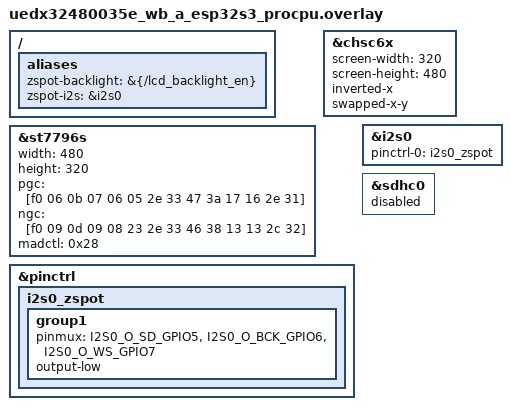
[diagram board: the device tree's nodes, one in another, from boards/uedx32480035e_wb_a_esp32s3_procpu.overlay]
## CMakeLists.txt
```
# Copyright (c) 2026 Muhammad Waleed Badar
# SPDX-License-Identifier: GPL-3.0-only

cmake_minimum_required(VERSION 3.20.0)

# When built from another west workspace, point Zephyr at this module.
if(NOT DEFINED ZEPHYR_EXTRA_MODULES)
  set(ZEPHYR_EXTRA_MODULES ${CMAKE_CURRENT_SOURCE_DIR}/..)
endif()

find_package(Zephyr REQUIRED HINTS $ENV{ZEPHYR_BASE})
project(zspot_player)

# --- Sources --------------------------------------------------------------

target_sources(app PRIVATE
  src/main.c
  src/certs.c
  src/webapi.c
  src/json_scan.c
)

target_sources_ifdef(CONFIG_WIFI_CREDENTIALS_CONNECT_STORED app PRIVATE src/wifi.c)
target_sources_ifdef(CONFIG_ZSPOT_CREDENTIALS_STORED        app PRIVATE src/credentials.c)
target_sources_ifdef(CONFIG_SETTINGS                        app PRIVATE src/track.c)
target_sources_ifdef(CONFIG_ZSPOT_PCM_TAP                   app PRIVATE src/pcm_tap.c)
target_sources_ifdef(CONFIG_ZSPOT_BATTERY                   app PRIVATE src/battery.c)

target_sources_ifdef(CONFIG_ZSPOT_UI app PRIVATE
  src/ui.c
  src/cover.c
  src/library.c
  src/lyrics.c
)

# --- TLS ------------------------------------------------------------------

# Mbed TLS is built with zspot_mbedtls_config.h (CONFIG_MBEDTLS_USER_CONFIG_FILE)
zephyr_include_directories(mbedtls)

# The root certificates that the servers are verified against
set(root_certs
  digicert_global_root_g2
  digicert_global_root_g3
  globalsign_root_r3
  gts_root_r4
  starfield_root_g2
)
foreach(cert ${root_certs})
  generate_inc_file_for_target(app
    certs/${cert}.der
    ${ZEPHYR_BINARY_DIR}/include/generated/certs/${cert}.der.inc
  )
endforeach()

# --- native_sim: west build -t run_tap ------------------------------------

if(CONFIG_ETH_NATIVE_TAP)
  if(DEFINED ENV{ZEPHYR_NET_TOOLS})
    set(net_tools $ENV{ZEPHYR_NET_TOOLS})
  else()
    set(net_tools ${ZEPHYR_BASE}/../tools/net-tools)
  endif()

  set(run_script ${CMAKE_CURRENT_SOURCE_DIR}/../scripts/native_sim_run.py)
  set(player     ${APPLICATION_BINARY_DIR}/zephyr/${KERNEL_EXE_NAME})

  add_custom_target(run_tap
    COMMAND ${PYTHON_EXECUTABLE} ${run_script} --net-tools ${net_tools} ${player}
    DEPENDS
      ${logical_target_for_zephyr_elf}
      $<$<TARGET_EXISTS:native_runner_executable>:native_runner_executable>
    WORKING_DIRECTORY ${APPLICATION_BINARY_DIR}
    USES_TERMINAL
  )
endif()
```

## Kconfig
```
# Copyright (c) 2026 Muhammad Waleed Badar
# SPDX-License-Identifier: GPL-3.0-only

mainmenu "zspot player"

menu "zspot player"

config ZSPOT_PCM_TAP
	bool "PCM tap: copy of the audio over TCP"
	select RING_BUFFER_LARGE
	help
	  Starts a TCP server that sends a copy of the PCM handed to the sink
	  (16-bit little-endian stereo at 44.1 kHz, before the sink applies the
	  volume) to a client, to hear on another machine what the output is
	  fed with:

	    nc <device> <port> | aplay -f S16_LE -r 44100 -c 2 \
	        -B 1000000 -R 1000000

	  A diagnostic aid: when the copy sounds right but the DAC does not,
	  the fault is in the I2S configuration, the wiring or the DAC.

config ZSPOT_PCM_TAP_PORT
	int "TCP port of the PCM tap"
	default 5000
	depends on ZSPOT_PCM_TAP

choice ZSPOT_AUDIO_QUALITY
	prompt "Stream quality"
	default ZSPOT_AUDIO_QUALITY_160
	help
	  Bit rate of the Ogg Vorbis stream that is asked for. A track that
	  does not come in it is played at 96 kbit/s. More takes more of the
	  network and of the processor.

config ZSPOT_AUDIO_QUALITY_96
	bool "96 kbit/s"

config ZSPOT_AUDIO_QUALITY_160
	bool "160 kbit/s"

config ZSPOT_AUDIO_QUALITY_320
	bool "320 kbit/s"

endchoice

config ZSPOT_AUDIO_FORMAT
	int
	default 0 if ZSPOT_AUDIO_QUALITY_96
	default 2 if ZSPOT_AUDIO_QUALITY_320
	default 1

config ZSPOT_USERNAME
	string "Spotify username (development only)"
	default ""
	help
	  Together with ZSPOT_PASSWORD, logs in with a username and
	  password instead of the zeroconf hand-over. Spotify no longer accepts
	  password logins from third-party clients for most accounts, but the
	  attempt still exercises access point resolution, the handshake and
	  the authentication exchange, which is useful on native_sim.

config ZSPOT_PASSWORD
	string "Spotify password (development only)"
	default ""

config ZSPOT_CREDENTIALS_JSON
	string "Stored credentials (JSON)"
	default ""
	help
	  Output of zspot_credentials_save_json() from a previous session. When
	  set, the sample skips the zeroconf hand-over.

config ZSPOT_CREDENTIALS_STORED
	bool "Keep the Spotify and the Web API credentials on the device"
	default y
	depends on SETTINGS
	select SECURE_STORAGE
	help
	  Stores the reusable credentials of a session in the settings and
	  signs in with them at the next start, so that the device does not
	  have to be picked in the Spotify app again. Credentials that Spotify
	  rejects are removed, and the device waits for the hand-over again.

	  The device then stays signed in to the account that picked it last,
	  until another one picks it in its Spotify app.

	  The credentials of the Web API are kept the same way, once a build
	  has carried them to the device (ZSPOT_WEB_CREDENTIALS_BUILT_IN).

	  Both go through the secure storage subsystem, which encrypts them
	  (AES-GCM) with a key derived from the ID of the device before they
	  reach the settings. That keeps them out of a plain copy of the
	  flash; it is no protection from somebody who also reads the device
	  ID, which takes the flash encryption of the SoC. Zephyr's Wi-Fi
	  credentials library keeps the Wi-Fi passwords in the secure storage
	  as well.

	  Credentials given to the build (ZSPOT_CREDENTIALS_JSON, or
	  ZSPOT_USERNAME and ZSPOT_PASSWORD) take precedence over stored ones.

# The credentials of a session are a JSON text of a few hundred bytes
configdefault SECURE_STORAGE_ITS_MAX_DATA_SIZE
	default 1024 if ZSPOT_CREDENTIALS_STORED

config ZSPOT_WEB_CREDENTIALS_BUILT_IN
	bool "Build the Web API credentials into the firmware"
	help
	  The last song after a restart, and "Your Library" and the search on
	  the Now Playing screen, use the Spotify Web API, which needs an
	  application registered at developer.spotify.com and a one-time
	  authorisation by the user with scripts/spotify_authorize.py. That
	  gives a client ID, a client secret and a refresh token.

	  With this option the build takes the three from its environment
	  (ZSPOT_WEB_CLIENT_ID, ZSPOT_WEB_CLIENT_SECRET and
	  ZSPOT_WEB_REFRESH_TOKEN) and makes them part of the firmware, where
	  they are plain text: whoever has the firmware file can read them.

	  A player that keeps credentials (ZSPOT_CREDENTIALS_STORED) stores
	  them encrypted at its first start and uses the stored ones from then
	  on. Build it with this option once, to carry them to the device, and
	  without it afterwards, so that the firmware no longer holds them.
	  Building with it again replaces the stored ones.

	  A player that has nowhere to store them has to be built with it
	  every time. Without credentials the library view only says that it
	  is not set up, and the last song is not offered after a restart.

if ZSPOT_WEB_CREDENTIALS_BUILT_IN

# The defaults come from the environment of the build, so that the values stay
# out of the repository and of the command line.

config ZSPOT_WEB_CLIENT_ID
	string "Client ID of the Spotify developer application"
	default "$(ZSPOT_WEB_CLIENT_ID)"

config ZSPOT_WEB_CLIENT_SECRET
	string "Client secret of the Spotify developer application"
	default "$(ZSPOT_WEB_CLIENT_SECRET)"

config ZSPOT_WEB_REFRESH_TOKEN
	string "Refresh token of the authorised user"
	default "$(ZSPOT_WEB_REFRESH_TOKEN)"

endif # ZSPOT_WEB_CREDENTIALS_BUILT_IN

config ZSPOT_UI
	bool "Now Playing screen (LVGL)"
	depends on LVGL && LV_Z_RUN_LVGL_ON_WORKQUEUE && LV_USE_TJPGD
	help
	  Shows the cover art, title, artist and progress of the current track
	  on the chosen display (the layout follows its resolution) and offers touch
	  controls for play/pause, skipping, seeking and the volume. See
	  prj.conf for the LVGL configuration it needs, and boards/<board>.conf
	  for what depends on the display of a board.

if ZSPOT_UI

config ZSPOT_BATTERY
	bool "Battery indicator"
	default y
	depends on $(dt_alias_enabled,fuel-gauge0)
	select FUEL_GAUGE
	help
	  Shows the charge level reported by the fuel gauge behind the
	  devicetree alias fuel-gauge0 next to the network indicator. Only
	  available when the board has that alias and its node is enabled.

config ZSPOT_BATTERY_POLL_SECONDS
	int "Seconds between two readings of the fuel gauge"
	default 30
	range 1 3600

config ZSPOT_SCREEN_TIMEOUT_SECONDS
	int "Seconds without a touch after which the screen turns off"
	default 60
	range 0 3600
	help
	  Turns the display off, and its backlight when the board has the
	  devicetree alias zspot-backlight (a regulator), once the screen has
	  not been touched for this long. The next touch turns it back on and
	  does nothing else. Playback is not affected. 0 keeps the screen on.

endif # ZSPOT_UI

endmenu # zspot player

source "Kconfig.zephyr"
```

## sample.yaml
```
# Copyright (c) 2026 Muhammad Waleed Badar
# SPDX-License-Identifier: GPL-3.0-only

sample:
  name: zspot player
  description: Spotify Connect player with a touchscreen UI (Now Playing, library, lyrics, Wi-Fi setup)
common:
  build_only: true
  tags: zspot
  platform_allow:
    - native_sim/native/64
  integration_platforms:
    - native_sim/native/64
tests:
  # As it is flashed and run
  app.zspot.player:
    platform_allow:
      - native_sim/native/64
      - uedx32480035e_wb_a/esp32s3/procpu
    integration_platforms:
      - native_sim/native/64
      - uedx32480035e_wb_a/esp32s3/procpu
  # What the board has and native_sim lacks: the settings, and with them the
  # stored credentials and the last song
  app.zspot.player.settings:
    extra_configs:
      - CONFIG_FLASH=y
      - CONFIG_FLASH_MAP=y
      - CONFIG_NVS=y
      - CONFIG_SETTINGS=y
  app.zspot.player.no_ui:
    extra_configs:
      - CONFIG_ZSPOT_UI=n
  # The stored credentials, the last song and the Web API do not need the screen
  app.zspot.player.no_ui.settings:
    extra_configs:
      - CONFIG_ZSPOT_UI=n
      - CONFIG_FLASH=y
      - CONFIG_FLASH_MAP=y
      - CONFIG_NVS=y
      - CONFIG_SETTINGS=y
  app.zspot.player.debug:
    extra_args: EXTRA_CONF_FILE=debug.conf
  # Options that leave code out or swap it: the PCM tap, the sink without a
  # buffer ahead of the output, servers that are not verified
  app.zspot.player.options:
    extra_configs:
      - CONFIG_ZSPOT_PCM_TAP=y
      - CONFIG_ZSPOT_I2S_BUFFER_MS=0
      - CONFIG_ZSPOT_TLS_SEC_TAG=-1
```

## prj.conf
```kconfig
# Copyright (c) 2026 Muhammad Waleed Badar
# SPDX-License-Identifier: GPL-3.0-only

# --- zspot ---------------------------------------------------------------
CONFIG_ZSPOT=y
CONFIG_ZSPOT_I2S_SINK=y
CONFIG_ZSPOT_UI=y

# --- C++ runtime for the protocol core -----------------------------------
CONFIG_CPP=y
CONFIG_STD_CPP20=y

# --- Memory ---------------------------------------------------------------
CONFIG_MAIN_STACK_SIZE=8192
# Wi-Fi connect requests run on the system workqueue; the Wi-Fi driver starts
# up in the caller's context, and the stored networks are read there through
# the secure storage, with buffers of an entry's size on the stack. That took
# 4.2 KB.
CONFIG_SYSTEM_WORKQUEUE_STACK_SIZE=6144
CONFIG_DYNAMIC_THREAD_POOL_SIZE=0
CONFIG_DYNAMIC_THREAD_PREFER_ALLOC=y

# --- Networking -----------------------------------------------------------
CONFIG_NETWORKING=y
CONFIG_NET_IPV4=y
CONFIG_NET_IPV6=n
CONFIG_NET_TCP=y
CONFIG_NET_UDP=y
CONFIG_NET_SOCKETS=y
CONFIG_NET_DHCPV4=y
CONFIG_NET_MGMT=y
CONFIG_NET_MGMT_EVENT=y
CONFIG_NET_MGMT_EVENT_INFO=y
CONFIG_NET_CONNECTION_MANAGER=n
CONFIG_NET_HOSTNAME_ENABLE=y
CONFIG_NET_HOSTNAME="zspot"
# The TCP receive window is a third of the RX buffer space (128 bytes each).
# With 64 buffers it was 2.7 KB, less than two segments, which throttled the
# audio download; 768 buffers make it 32 KB.
CONFIG_NET_PKT_RX_COUNT=64
CONFIG_NET_BUF_RX_COUNT=768
CONFIG_NET_PKT_TX_COUNT=64
CONFIG_NET_BUF_TX_COUNT=768
# The audio CDN, the track look-up, the cover, the lyrics and the Web API at a
# track change, the access point, the two endpoints that listen, mDNS, DNS and
# DHCP, and connections that were closed a moment ago and still linger: with
# 12, a few requests in a row to an endpoint were refused
CONFIG_NET_MAX_CONN=16
CONFIG_NET_MAX_CONTEXTS=16

CONFIG_NET_RX_STACK_SIZE=4096
CONFIG_NET_TCP_WORKQ_STACK_SIZE=4096
# The thread that takes DNS answers and answers mDNS queries. On the ESP32-S3
# an answer to a browse for the Spotify Connect service takes 1.6 KB of stack,
# more than the 1536 bytes that Zephyr gives it with the mDNS responder
CONFIG_NET_SOCKETS_SERVICE_STACK_SIZE=2560

CONFIG_ZVFS_OPEN_MAX=20
CONFIG_ZVFS_POLL_MAX=16

# DNS: resolver gets the servers from DHCP, static fallback below
CONFIG_DNS_RESOLVER=y
CONFIG_DNS_SERVER_IP_ADDRESSES=y
CONFIG_DNS_SERVER1="8.8.8.8"
CONFIG_DNS_RESOLVER_MAX_SERVERS=3
# At a track change the audio CDN, the cover, the lyrics and the Web API are
# looked up at the same time; with the default of one query at a time the
# others fail at once ("DNS lookup ... failed (-3)")
CONFIG_DNS_NUM_CONCUR_QUERIES=4

# mDNS / DNS-SD for discovery by the Spotify app
CONFIG_MDNS_RESPONDER=y
CONFIG_DNS_SD=y
CONFIG_MDNS_RESPONDER_DNS_SD=y

# --- TLS (Spotify endpoints: TLS 1.2, ECDHE-RSA, AES-GCM) -----------------
CONFIG_MBEDTLS=y
CONFIG_MBEDTLS_ENABLE_HEAP=y
# Sessions: access point resolution/metadata, audio CDN and the cover art
CONFIG_MBEDTLS_HEAP_SIZE=163840
CONFIG_MBEDTLS_SSL_IN_CONTENT_LEN=16384
CONFIG_MBEDTLS_SSL_OUT_CONTENT_LEN=4096
CONFIG_MBEDTLS_SSL_PROTO_TLS1_2=y
CONFIG_MBEDTLS_SSL_SERVER_NAME_INDICATION=y
CONFIG_MBEDTLS_KEY_EXCHANGE_ECDHE_RSA_ENABLED=y
CONFIG_MBEDTLS_CIPHERSUITE_TLS_ECDHE_RSA_WITH_AES_128_GCM_SHA256=y
CONFIG_MBEDTLS_CIPHERSUITE_TLS_ECDHE_RSA_WITH_AES_256_GCM_SHA384=y
# The lyrics service (lrclib.net) only offers ECDSA certificates
CONFIG_MBEDTLS_KEY_EXCHANGE_ECDHE_ECDSA_ENABLED=y
CONFIG_MBEDTLS_CIPHERSUITE_TLS_ECDHE_ECDSA_WITH_AES_128_GCM_SHA256=y
CONFIG_MBEDTLS_X509_CRT_PARSE_C=y
# The AES tables come with the image instead of being computed into 8 KB of
# RAM at the first use
CONFIG_MBEDTLS_AES_ROM_TABLES=y
CONFIG_PSA_CRYPTO=y
CONFIG_PSA_WANT_ALG_SHA_256=y
CONFIG_PSA_WANT_ALG_SHA_384=y
CONFIG_PSA_WANT_ALG_GCM=y
CONFIG_PSA_WANT_ALG_ECDH=y
CONFIG_PSA_WANT_ECC_SECP_R1_256=y
CONFIG_PSA_WANT_ECC_SECP_R1_384=y
CONFIG_PSA_WANT_KEY_TYPE_ECC_KEY_PAIR_GENERATE=y
CONFIG_PSA_WANT_ALG_RSA_PKCS1V15_SIGN=y
CONFIG_PSA_WANT_ALG_ECDSA=y
CONFIG_PSA_WANT_KEY_TYPE_ECC_PUBLIC_KEY=y
CONFIG_PSA_WANT_KEY_TYPE_RSA_PUBLIC_KEY=y
CONFIG_NET_SOCKETS_SOCKOPT_TLS=y
CONFIG_NET_SOCKETS_TLS_MAX_CONTEXTS=6
# The servers are verified against the root certificates in certs/, which the
# application registers under these tags. A tag of -1 turns that off.
CONFIG_TLS_CREDENTIALS=y
CONFIG_TLS_MAX_CREDENTIALS_NUMBER=8
CONFIG_NET_SOCKETS_TLS_MAX_CREDENTIALS=8
CONFIG_ZSPOT_TLS_SEC_TAG=100
CONFIG_ZSPOT_TLS_SEC_TAG_COUNT=5
# Sessions that are resumed instead of negotiated anew: one per server that is
# connected to again and again (track look-up, audio CDN, cover, Web API and
# its token, lyrics). The tickets for that come with zspot_mbedtls_config.h.
CONFIG_NET_SOCKETS_TLS_MAX_CLIENT_SESSION_COUNT=6
CONFIG_MBEDTLS_USER_CONFIG_FILE="zspot_mbedtls_config.h"
CONFIG_ENTROPY_GENERATOR=y

# --- Display: "Now Playing" screen (LVGL) ----------------------------------
# What depends on the display of a board is in boards/<board>.conf: its colour
# depth and formats, larger fonts, where the memory pool lives.
CONFIG_DISPLAY=y
CONFIG_INPUT=y
# Touch events queue up while the LVGL thread is busy (e.g. in a zspot call);
# with the default sizes drags lose events ("Could not put input data into
# queue")
CONFIG_INPUT_QUEUE_MAX_MSGS=64
CONFIG_LV_Z_POINTER_INPUT_MSGQ_COUNT=64
CONFIG_LVGL=y
CONFIG_LV_Z_POINTER_INPUT=y
# LVGL runs on its own workqueue; the touch handlers call into zspot from it
# (protobuf encoding, socket I/O), hence the stack
CONFIG_LV_Z_RUN_LVGL_ON_WORKQUEUE=y
CONFIG_LV_Z_LVGL_MUTEX=y
CONFIG_LV_Z_LVGL_WORKQUEUE_STACK_SIZE=16384
# Below the zspot threads (CONFIG_ZSPOT_THREAD_PRIORITY and higher): drawing
# must not take the processor from the audio decoder
CONFIG_LV_Z_LVGL_WORKQUEUE_PRIORITY=8
CONFIG_LV_Z_FLUSH_THREAD=y
CONFIG_LV_Z_FLUSH_THREAD_PRIORITY=8
# Holds the widgets, the cover art (the downloaded JPEG, up to 96 KB, and the
# decoded RGB565 image, 180 KB at 300x300, briefly two of the latter), the
# Web API responses of the library view (160 KB) and the lyrics (80 KB while
# they load)
CONFIG_LV_Z_MEM_POOL_SIZE=1048576
CONFIG_LV_USE_LABEL=y
CONFIG_LV_USE_IMAGE=y
CONFIG_LV_USE_BAR=y
CONFIG_LV_USE_SLIDER=y
# Password entry of the Wi-Fi settings
CONFIG_LV_USE_TEXTAREA=y
CONFIG_LV_USE_BUTTONMATRIX=y
CONFIG_LV_USE_KEYBOARD=y
CONFIG_LV_THEME_DEFAULT_DARK=y
# The covers are JPEG
CONFIG_LV_USE_TJPGD=y
# The fonts of a 320x480 display. The UI scales with the resolution: a board
# with a larger display adds 18, 30 and 40 (one and a half times the size) or
# 24, 40 and 48 (twice the size) in boards/<board>.conf, and the UI takes them.
CONFIG_LV_FONT_MONTSERRAT_12=y
CONFIG_LV_FONT_MONTSERRAT_14=y
CONFIG_LV_FONT_MONTSERRAT_20=y
CONFIG_LV_FONT_MONTSERRAT_28=y

# --- Wi-Fi (wifi_credentials library, settings/NVS backend) ----------------
# The Wi-Fi driver is selected per board; boards without Wi-Fi override this
# block (see boards/native_sim_native_64.conf).
CONFIG_WIFI=y
CONFIG_WIFI_CREDENTIALS=y
CONFIG_WIFI_CREDENTIALS_CONNECT_STORED=y
CONFIG_FLASH=y
CONFIG_FLASH_MAP=y
CONFIG_NVS=y
CONFIG_SETTINGS=y
CONFIG_NET_MGMT_EVENT_QUEUE_SIZE=16
CONFIG_NET_MGMT_EVENT_STACK_SIZE=4096

# --- Speed ----------------------------------------------------------------
CONFIG_SPEED_OPTIMIZATIONS=y

# --- Logging --------------------------------------------------------------
# Off to save processor time and memory: the console then reports nothing,
# not even I2S underruns or fatal errors. To turn it on, build with
# -DEXTRA_CONF_FILE=debug.conf.
CONFIG_NET_LOG=n
CONFIG_LOG_MODE_IMMEDIATE=n
```

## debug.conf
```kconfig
# Copyright (c) 2026 Muhammad Waleed Badar
# SPDX-License-Identifier: GPL-3.0-only
#
# The log on the console, which the player is built without. Add it with
#
#   west build -b <board> zspot/app -- -DEXTRA_CONF_FILE=debug.conf
#
# It costs processor time and memory: not for listening.

CONFIG_LOG=y
CONFIG_ZSPOT_LOG_LEVEL_INF=y
# A fault names the thread and where its stack ran out
CONFIG_THREAD_NAME=y
CONFIG_STACK_SENTINEL=y
```

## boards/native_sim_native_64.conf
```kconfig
# Copyright (c) 2026 Muhammad Waleed Badar
# SPDX-License-Identifier: GPL-3.0-only
#
# native_sim/native/64: Zephyr IP stack over the host TAP interface (zeth).
# "west build -t run_tap" creates it with Zephyr's net-tools before the player
# starts and removes it once the player has ended (scripts/native_sim_run.py).
# Zephyr uses 192.0.2.1, the host side is 192.0.2.2 (gateway and NAT).

CONFIG_NET_L2_ETHERNET=y
CONFIG_ETH_NATIVE_TAP=y
CONFIG_NET_DHCPV4=n
CONFIG_NET_CONFIG_SETTINGS=y
CONFIG_NET_CONFIG_NEED_IPV4=y
CONFIG_NET_CONFIG_MY_IPV4_ADDR="192.0.2.1"
CONFIG_NET_CONFIG_MY_IPV4_NETMASK="255.255.255.0"
CONFIG_NET_CONFIG_MY_IPV4_GW="192.0.2.2"
CONFIG_NET_CONFIG_PEER_IPV4_ADDR="192.0.2.2"

# No Wi-Fi and no flash-backed settings: override the generic Wi-Fi block
CONFIG_WIFI=n
CONFIG_WIFI_CREDENTIALS=n
CONFIG_WIFI_CREDENTIALS_CONNECT_STORED=n
CONFIG_SETTINGS=n
CONFIG_NVS=n
CONFIG_FLASH=n
CONFIG_FLASH_MAP=n

# The audio goes through the native_sim I2S driver (the zspot-i2s alias in the
# overlay) to the host's default ALSA device. Another device or a file is
# picked with --i2s_tx_tx=<path>, e.g. alsa:hw:0,0 or out.pcm.
CONFIG_I2S_NATIVE_SIM_ALSA=y
# Host RAM is plentiful: buffer ahead of the output as on the ESP32, so that
# the output keeps running while the player fetches the next piece of a track.
CONFIG_ZSPOT_I2S_BUFFER_MS=2000

# The SDL display (an on-screen window, the mouse acts as the touch screen) is
# ARGB8888
CONFIG_LV_COLOR_DEPTH_32=y

# Protocol thread stacks are heap allocated; host RAM is plentiful
CONFIG_HEAP_MEM_POOL_SIZE=262144

CONFIG_ENTROPY_GENERATOR=y
CONFIG_FAKE_ENTROPY_NATIVE_SIM=y
```

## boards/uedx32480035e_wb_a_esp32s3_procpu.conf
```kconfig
# Copyright (c) 2026 Muhammad Waleed Badar
# SPDX-License-Identifier: GPL-3.0-only
#
# UEDX32480035E-WB-A: 3.5" 320x480 touch display (ST7796S over SPI), used in
# landscape. What LVGL needs for this display; the rest of its configuration
# is in prj.conf, and what the board needs of the SoC in
# socs/esp32s3_procpu.conf.

# The LVGL memory pool, which also serves the UI's own buffers and the stacks
# of its threads, lives in PSRAM (the SoC linker script places the .lvgl_heap
# section there).
#
# The render buffer stays in internal RAM (30 KB): the display's SPI driver
# sends it with DMA, which cannot read from PSRAM. From there the driver has
# to copy every 4 KB chunk into a buffer from the kernel heap, and fails with
# "Error allocating temp buffer Tx" when that heap is short. For the same
# reason the .bss of the LVGL library, which holds that buffer, is not
# relocated to PSRAM.
CONFIG_LV_Z_MEMORY_POOL_CUSTOM_SECTION=y

# The panel is drawn in RGB565. The symbols are A8, a cover that is scaled
# passes through RGB565A8, and what is shown dimmed through ARGB8888; the
# renderer does without the other colour formats.
CONFIG_LV_DRAW_SW_SUPPORT_RGB888=n
CONFIG_LV_DRAW_SW_SUPPORT_XRGB8888=n
CONFIG_LV_DRAW_SW_SUPPORT_ARGB8888_PREMULTIPLIED=n
CONFIG_LV_DRAW_SW_SUPPORT_L8=n
CONFIG_LV_DRAW_SW_SUPPORT_AL88=n
CONFIG_LV_DRAW_SW_SUPPORT_I1=n
```

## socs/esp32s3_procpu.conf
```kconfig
# Copyright (c) 2026 Muhammad Waleed Badar
# SPDX-License-Identifier: GPL-3.0-only

# --- Speed ----------------------------------------------------------------
# Largest caches the ESP32-S3 offers: code runs from flash and every page
# buffer lives in PSRAM, both go through these caches. 64-byte data lines
# suit the renderer's sequential access to tiles and masks.
CONFIG_SOC_ESP32S3_INSTRUCTION_CACHE_32KB=y
CONFIG_SOC_ESP32S3_INSTRUCTION_CACHE_8WAYS=y
CONFIG_SOC_ESP32S3_INSTRUCTION_CACHE_LINE_32B=y
CONFIG_SOC_ESP32S3_DATA_CACHE_64KB=y
CONFIG_SOC_ESP32S3_DATA_CACHE_8WAYS=y
CONFIG_SOC_ESP32S3_DATA_CACHE_LINE_64B=y
# The modem does not sleep between beacons, which held packets back at the
# access point; the radio draws its active current all the time instead
CONFIG_ESP32_WIFI_STA_POWER_SAVE_NONE=y
# Code and constants are copied from the flash into PSRAM at start-up (2 MB of
# the 8) and run from there: the octal PSRAM is read faster than the quad
# flash. With both set, the HAL also leaves the cache on while it writes to
# the flash, so that the rest of the system is not held up for as long as a
# sector takes to erase.
CONFIG_SOC_FAMILY_ESPRESSIF_SPIRAM_FETCH_INSTRUCTIONS=y
CONFIG_SOC_FAMILY_ESPRESSIF_SPIRAM_RODATA=y
# Octal PSRAM and flash at 80 MHz, flash in quad I/O mode
CONFIG_SOC_FAMILY_ESPRESSIF_SPIRAM_SPEED_80M=y
CONFIG_SOC_FAMILY_ESPRESSIF_FLASH_FREQ_80M=y
CONFIG_SOC_FAMILY_ESPRESSIF_FLASH_MODE_QIO=y
# -O3 on top of CONFIG_SPEED_OPTIMIZATIONS (prj.conf); flash has room
CONFIG_COMPILER_OPT="-O3"

# 8 MB octal PSRAM (enabled by the board); keep Wi-Fi and net buffers there too
CONFIG_ESP_WIFI_HEAP_SPIRAM=y
CONFIG_ESP32_WIFI_NET_ALLOC_SPIRAM=y

CONFIG_ESP32_WIFI_STATIC_RX_BUFFER_NUM=8
CONFIG_ESP32_WIFI_DYNAMIC_RX_BUFFER_NUM=16
CONFIG_ESP32_WIFI_DYNAMIC_TX_BUFFER_NUM=16

# libc heap in internal RAM (nanopb and small objects; large buffers use PSRAM)
CONFIG_COMMON_LIBC_MALLOC_ARENA_SIZE=40960
# The .bss of the socket layer goes to PSRAM: 17 KB, nearly all of it the TLS
# socket contexts (CONFIG_NET_SOCKETS_TLS_MAX_CONTEXTS)
CONFIG_SOC_FAMILY_ESPRESSIF_SPIRAM_BSS_RELOC_LIBS_AND_OBJS="libsubsys__net.a"

# The Mbed TLS heap is relocated to PSRAM (ZSPOT_EXTERNAL_TLS_HEAP_SIZE); keep the static one small
CONFIG_MBEDTLS_HEAP_SIZE=4096
# Audio, cover, lyrics and Web API sessions overlap at a track change; the
# default of 96 KB ran out ("TLS handshake error: -0x8d")
CONFIG_ZSPOT_EXTERNAL_TLS_HEAP_SIZE=262144

# I2S slab: 6 blocks of 4 KB
CONFIG_ZSPOT_I2S_BLOCK_COUNT=6
```

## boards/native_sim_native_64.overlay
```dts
/*
 * Copyright (c) 2026 Muhammad Waleed Badar
 *
 * SPDX-License-Identifier: GPL-3.0-only
 */

/*
 * The audio goes out through the I2S driver of the board, to the host's
 * ALSA device (see native_sim_native_64.conf).
 */
/ {
	aliases {
		zspot-i2s = &i2s_tx0;
	};
};

&fuel_gauge0 {
	status = "okay";
};

&sdl_dc {
	width = <320>;
	height = <480>;
};
```

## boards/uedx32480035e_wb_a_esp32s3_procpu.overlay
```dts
/*
 * Copyright (c) 2026 Muhammad Waleed Badar
 *
 * SPDX-License-Identifier: GPL-3.0-only
 */

/* Turned off together with the display by the screen timeout. */
/ {
	aliases {
		zspot-backlight = &{/lcd_backlight_en};
		zspot-i2s = &i2s0;
	};
};

/*
 * VIEWE UEDX32480035E-WB-A in landscape (480x320).
 *
 * MADCTL: MV (0x20) exchanges rows and columns, BGR (0x08) is the colour
 * order of the panel. The board's portrait value is 0x48 (MX | BGR). If the
 * picture is upside down for the way the board is mounted, use 0xe8
 * (MY | MX | MV | BGR), and for the touch "inverted-y" instead of
 * "inverted-x".
 */
&st7796s {
	width = <480>;
	height = <320>;
	pgc = [f0 06 0b 07 06 05 2e 33 47 3a 17 16 2e 31];
	ngc = [f0 09 0d 09 08 23 2e 33 46 38 13 13 2c 32];
	madctl = <0x28>;
};

/*
 * The touch controller keeps reporting in the panel's own 320x480 space,
 * which screen-width and screen-height describe. Landscape x is the panel's
 * y, and landscape y runs against the panel's x.
 */
&chsc6x {
	screen-width = <320>;
	screen-height = <480>;
	inverted-x;
	swapped-x-y;
};

&pinctrl {
	i2s0_zspot: i2s0_zspot {
		group1 {
			pinmux = <I2S0_O_SD_GPIO5>,	/* DIN */
				 <I2S0_O_BCK_GPIO6>,
				 <I2S0_O_WS_GPIO7>;	/* LRC */

			output-low;
		};
	};
};

&i2s0 {
	status = "okay";
	pinctrl-0 = <&i2s0_zspot>;
	pinctrl-names = "default";
};

/* Not needed by the player; frees the SDMMC pins and driver memory. */
&sdhc0 {
	status = "disabled";
};
```

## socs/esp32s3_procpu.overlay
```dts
/*
 * Copyright (c) 2026 Muhammad Waleed Badar
 *
 * SPDX-License-Identifier: GPL-3.0-only
 */

/*
 * VIEWE UEDX32480035E-WB-A (ESP32-S3): external I2S DAC on free GPIOs.
 * DATA = GPIO5, BCK = GPIO6, WS (LRCK) = GPIO7. The remaining GPIOs are used
 * by the display, touch, SD card, USB, RGB LED and buzzer.
 */

/ {
	aliases {
		zspot-i2s = &i2s0;
	};
};

&pinctrl {
	i2s0_zspot: i2s0_zspot {
		group1 {
			pinmux = <I2S0_O_SD_GPIO5>,	/* DIN */
				 <I2S0_O_BCK_GPIO6>,
				 <I2S0_O_WS_GPIO7>;	/* LRC */

			output-low;
		};
	};
};

&i2s0 {
	status = "okay";
	pinctrl-0 = <&i2s0_zspot>;
	pinctrl-names = "default";
};

/* Not needed by the player; frees the SDMMC pins and driver memory. */
&sdhc0 {
	status = "disabled";
};
```

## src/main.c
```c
/*
 * Copyright (c) 2026 Muhammad Waleed Badar
 *
 * SPDX-License-Identifier: GPL-3.0-only
 */

/*
 * zspot player: Spotify Connect receiver with I2S output and a touchscreen UI.
 *
 * Flow: bring the network up, advertise the device, wait for the Spotify app
 * to hand over credentials (or use stored ones), connect, and route decoded
 * PCM to the I2S sink. With CONFIG_ZSPOT_UI a "Now Playing" screen shows
 * the track and controls playback.
 */
#include <errno.h>
#include <stdbool.h>
#include <stdio.h>
#include <string.h>

#include <zephyr/device.h>
#include <zephyr/kernel.h>
#include <zephyr/sys/atomic.h>
#include <zephyr/logging/log.h>
#include <zephyr/net/net_event.h>
#include <zephyr/net/net_if.h>
#include <zephyr/net/net_mgmt.h>
#include <zephyr/net/dhcpv4.h>

#include <zspot/zspot.h>

#if defined(CONFIG_WIFI_CREDENTIALS_CONNECT_STORED)
#include "wifi.h"
#endif
#if defined(CONFIG_ZSPOT_I2S_SINK)
#include <zspot/zspot_i2s_sink.h>
#endif
#include "pcm_tap.h"
#include "ui.h"
#include "battery.h"
#include "certs.h"
#include "credentials.h"
#include "track.h"
#include "webapi.h"
#if defined(CONFIG_ZSPOT_UI)
#include "library.h"
#include "lyrics.h"
#endif

/* Decoded PCM: 44.1 kHz, 16 bit, stereo */
#define PCM_BYTES_PER_SECOND (44100 * 4)

/* What the I2S driver has left to play when the sink has passed everything on */
#if defined(CONFIG_ZSPOT_I2S_SINK)
#define SINK_TAIL_MS                                                                               \
	(CONFIG_ZSPOT_I2S_BLOCK_COUNT * CONFIG_ZSPOT_I2S_BLOCK_SIZE * 1000 / PCM_BYTES_PER_SECOND)
#else
#define SINK_TAIL_MS 0
#endif

/* How often the main thread looks while the end of the queue is due, and otherwise */
#define END_POLL_MS  50
#define IDLE_POLL_MS 250

LOG_MODULE_REGISTER(zspot_player, LOG_LEVEL_INF);

static K_SEM_DEFINE(ipv4_ready, 0, 1);
static struct net_mgmt_event_callback net_cb;

static volatile bool paused;

/*
 * Playback position: where the track was (re)started plus the PCM handed to
 * the sink since then.
 */
static volatile uint32_t position_base_ms;
static atomic_t position_bytes;
/* PLAYBACK_START already set the position of the track that begins next */
static bool position_preset;
/* The track that begins was started anew: the sink is empty, no audio goes out */
static bool output_idle;

/*
 * End of playback: when the decoder is through with the last track of the
 * queue, the sink still plays what it buffered. The main thread tells Spotify
 * that playback ended once that audio is out, unless something else was
 * started in the meantime.
 */
static K_SEM_DEFINE(end_sem, 0, 1);
static atomic_t end_pending;
/* PCM went to the sink since the last end; a track that cannot be loaded ends without */
static atomic_t audio_played;
/* When the sink had passed on the last of the audio; 0 while it holds some */
static int64_t end_drained_ms;

/* The credentials of the session, to print them when they are not stored */
static char credentials_json[1024];

static void position_set(uint32_t position_ms)
{
	position_base_ms = position_ms;
	atomic_clear(&position_bytes);
}

/* Something else plays or the audio was dropped: there is no end to report. */
static void end_cancel(void)
{
	atomic_clear(&end_pending);
}

/* PCM that the sink accepted and has not passed on to the I2S driver yet */
static size_t sink_buffered(void)
{
#if defined(CONFIG_ZSPOT_I2S_SINK)
	return zspot_i2s_sink_buffered();
#else
	return 0;
#endif
}

/* Polled by the Now Playing screen */
static __maybe_unused uint32_t position_get(void)
{
	int64_t bytes = atomic_get(&position_bytes);

	/* What the sink still holds is not audible yet. */
	bytes = MAX(bytes - (int64_t)sink_buffered(), 0);
	return position_base_ms + (uint32_t)(bytes * 1000 / PCM_BYTES_PER_SECOND);
}

static void net_event_handler(struct net_mgmt_event_callback *cb, uint64_t event,
			      struct net_if *iface)
{
	ARG_UNUSED(cb);
	ARG_UNUSED(iface);

	if (event == NET_EVENT_IPV4_ADDR_ADD) {
		k_sem_give(&ipv4_ready);
	}
}

static int network_connect(void)
{
	struct net_if *iface = net_if_get_default();

	if (iface == NULL) {
		LOG_ERR("No network interface");
		return -ENODEV;
	}

	net_mgmt_init_event_callback(&net_cb, net_event_handler, NET_EVENT_IPV4_ADDR_ADD);
	net_mgmt_add_event_callback(&net_cb);

#if defined(CONFIG_WIFI_CREDENTIALS_CONNECT_STORED)
	/* Credentials come from the wifi_credentials library (settings backend). */
	int ret = wifi_init();

	if (ret != 0) {
		LOG_ERR("Wi-Fi init failed (%d)", ret);
		return ret;
	}
#endif

#if defined(CONFIG_NET_DHCPV4)
	/* The client waits for the interface to come up before sending DISCOVER. */
	net_dhcpv4_start(iface);
#endif

	/* A static address (CONFIG_NET_CONFIG_SETTINGS) is assigned before main() runs. */
	if (net_if_ipv4_get_global_addr(iface, NET_ADDR_PREFERRED) == NULL) {
		LOG_INF("Waiting for an IPv4 address...");
		k_sem_take(&ipv4_ready, K_FOREVER);
	}
	LOG_INF("Network ready");
	ui_set_network(true);
	return 0;
}

static void sink_flush(void)
{
#if defined(CONFIG_ZSPOT_I2S_SINK)
	zspot_i2s_sink_flush();
#endif
}

static void sink_set_volume(uint16_t volume)
{
#if defined(CONFIG_ZSPOT_I2S_SINK)
	zspot_i2s_sink_set_volume(volume);
#else
	ARG_UNUSED(volume);
#endif
}

static int sink_init(void)
{
#if defined(CONFIG_ZSPOT_I2S_SINK)
#if defined(CONFIG_I2S_NATIVE_SIM)
	/* An ALSA device ("alsa:<name>") or a host file */
	LOG_INF("Audio output: %s (--%s_tx=<path> overrides)", CONFIG_I2S_NATIVE_SIM_TX_PATH,
		DEVICE_DT_NAME(DT_ALIAS(zspot_i2s)));
#endif
	return zspot_i2s_sink_init(DEVICE_DT_GET(DT_ALIAS(zspot_i2s)),
				   DEVICE_DT_GET_OR_NULL(DT_ALIAS(zspot_codec)), 44100, 2, 16);
#else
	return 0;
#endif
}

static size_t sink_write(const uint8_t *pcm, size_t len, void *user_data)
{
#if defined(CONFIG_ZSPOT_I2S_SINK)
	return zspot_i2s_sink_write(pcm, len, user_data);
#else
	ARG_UNUSED(pcm);
	ARG_UNUSED(user_data);
	return len;
#endif
}

static void on_event(const struct zspot_event *event, void *user_data)
{
	ARG_UNUSED(user_data);

	switch (event->type) {
	case ZSPOT_EVENT_PLAY_PAUSE:
		LOG_INF("%s", event->paused ? "Paused" : "Playing");
		paused = event->paused;
#if defined(CONFIG_ZSPOT_I2S_SINK)
		zspot_i2s_sink_set_paused(event->paused);
#endif
		ui_set_paused(event->paused);
		/* Not for a track that is loaded paused: it is not known yet */
		if (event->paused && !position_preset) {
			track_set_position(position_get());
		}
		break;
	case ZSPOT_EVENT_VOLUME:
		LOG_INF("Volume %u", event->volume);
		sink_set_volume(event->volume);
		ui_set_volume(event->volume);
		break;
	case ZSPOT_EVENT_TRACK_INFO:
		LOG_INF("Now playing: %s - %s (%s)", event->track.artist, event->track.name,
			event->track.album);
		ui_show_track(event->track.name, event->track.artist, event->track.image_url,
			      event->track.duration_ms);
		track_set(&event->track, position_get(), output_idle);
		break;
	case ZSPOT_EVENT_SEEK:
		LOG_INF("Seek to %u ms", event->position_ms);
		end_cancel();
		sink_flush();
		position_set(event->position_ms);
		track_set_position(event->position_ms);
		break;
	case ZSPOT_EVENT_FLUSH:
		end_cancel();
		sink_flush();
		break;
	case ZSPOT_EVENT_PLAYBACK_START:
		end_cancel();
		track_playback_begun();
		sink_flush();
		position_set(event->position_ms);
		position_preset = true;
		break;
	case ZSPOT_EVENT_TRACK_BEGIN:
		end_cancel();
		track_playback_begun();
		/* A gapless transition comes without PLAYBACK_START. */
		if (!position_preset) {
			position_set(0);
		}
		output_idle = position_preset;
		position_preset = false;
		zspot_notify_audio_reached_playback();
		break;
	case ZSPOT_EVENT_QUEUE_CHANGED:
		end_cancel();
		track_set_context(event->context_uri);
		track_playback_begun();
		break;
	case ZSPOT_EVENT_DISCONNECT:
		LOG_INF("Playback moved to another device");
		end_cancel();
		track_set_position(position_get());
		sink_flush();
		ui_show_message("Playing on another device",
				"Pick this device in Spotify to listen here");
		break;
	case ZSPOT_EVENT_NEXT:
	case ZSPOT_EVENT_PREV:
		end_cancel();
		sink_flush();
		break;
	case ZSPOT_EVENT_DEPLETED:
		LOG_INF("Queue finished");
		if (atomic_clear(&audio_played)) {
			atomic_set(&end_pending, 1);
			k_sem_give(&end_sem);
		}
		break;
	case ZSPOT_EVENT_REPEAT:
		LOG_INF("Repeat %s", event->repeat == ZSPOT_REPEAT_TRACK ? "track"
				     : event->repeat == ZSPOT_REPEAT_ALL ? "all"
									  : "off");
		ui_set_repeat((enum ui_repeat)event->repeat);
		break;
	case ZSPOT_EVENT_CONNECTION_LOST:
		LOG_WRN("Connection to Spotify lost, reconnecting");
		ui_set_network(false);
		break;
	case ZSPOT_EVENT_CONNECTION_RESTORED:
		LOG_INF("Connection to Spotify restored");
		ui_set_network(true);
		break;
	}
}

static size_t on_pcm(const uint8_t *pcm, size_t len, void *user_data)
{
	size_t accepted;

	if (paused) {
		return 0; /* player retries shortly */
	}

	accepted = sink_write(pcm, len, user_data);
	if (accepted > 0) {
		atomic_set(&audio_played, 1);
	}
	atomic_add(&position_bytes, accepted);
	pcm_tap_write(pcm, accepted);
	return accepted;
}

/*
 * Reports the end of the queue once the last audio has been played. Called
 * again and again from the main thread: the event comes from the player
 * thread, which must not be held up for that long.
 */
static void end_poll(void)
{
	/* A pause keeps the audio in the sink, and the end waiting. */
	if (!atomic_get(&end_pending) || sink_buffered() > 0) {
		end_drained_ms = 0;
		return;
	}

	/* The I2S driver still plays what it was handed last */
	if (end_drained_ms == 0) {
		end_drained_ms = k_uptime_get();
	}
	if (k_uptime_get() - end_drained_ms < SINK_TAIL_MS) {
		return;
	}

	end_drained_ms = 0;
	if (atomic_cas(&end_pending, 1, 0)) {
		LOG_INF("Playback ended");
		zspot_notify_audio_ended();
	}
}

#if defined(CONFIG_ZSPOT_UI)
/*
 * While the song shown after a restart waits to be started, Play and the
 * progress slider act on it; there is no queue yet to skip in.
 */
static void ui_pause(bool pause)
{
	if (!track_pause(pause)) {
		zspot_set_pause(pause);
	}
}

static void ui_seek(uint32_t position_ms)
{
	if (!track_seek(position_ms)) {
		zspot_seek(position_ms);
	}
}

static void ui_next(void)
{
	if (!track_waiting() && zspot_next()) {
		end_cancel();
		sink_flush();
	}
}

static void ui_previous(void)
{
	if (!track_waiting() && zspot_previous()) {
		end_cancel();
		sink_flush();
	}
}

/* The button shows the modes of the library under its own names */
BUILD_ASSERT((int)UI_REPEAT_OFF == (int)ZSPOT_REPEAT_OFF &&
	     (int)UI_REPEAT_ALL == (int)ZSPOT_REPEAT_ALL &&
	     (int)UI_REPEAT_TRACK == (int)ZSPOT_REPEAT_TRACK);

static void ui_repeat(enum ui_repeat mode)
{
	zspot_set_repeat((enum zspot_repeat)mode);
}

static void ui_volume(uint16_t volume, bool commit)
{
	sink_set_volume(volume);
	if (commit) {
		zspot_set_volume(volume);
	}
}

#if !defined(CONFIG_WIFI_CREDENTIALS_CONNECT_STORED)
/* Boards without Wi-Fi, such as native_sim, are connected by other means. */
static void wifi_scan(void)
{
	ui_list_reset(UI_LIST_WIFI, 1, "Wi-Fi", true, "This board has no Wi-Fi");
}

static void wifi_join(const char *ssid, const char *password)
{
	ARG_UNUSED(ssid);
	ARG_UNUSED(password);
}

static void wifi_forget(const char *ssid)
{
	ARG_UNUSED(ssid);
}
#endif

static const struct ui_ops ui_ops = {
	.set_paused = ui_pause,
	.next = ui_next,
	.previous = ui_previous,
	.set_repeat = ui_repeat,
	.seek = ui_seek,
	.set_volume = ui_volume,
	.position_ms = position_get,
	.library_open = library_open,
	.library_back = library_back,
	.library_select = library_select,
	.wifi_scan = wifi_scan,
	.wifi_connect = wifi_join,
	.wifi_forget = wifi_forget,
	.lyrics_request = lyrics_request,
	.search = library_search,
	.search_select = library_search_select,
};
#endif

/* The values of the option are those of enum zspot_audio_format */
BUILD_ASSERT(ZSPOT_FORMAT_OGG_VORBIS_96 == 0 && ZSPOT_FORMAT_OGG_VORBIS_160 == 1 &&
	     ZSPOT_FORMAT_OGG_VORBIS_320 == 2);

/* A start-up step failed for good: the player stays as it is. */
static void show_failure(const char *what, int error)
{
	char detail[UI_TEXT_MAX];

	snprintf(detail, sizeof(detail), "Error %d. Restart the device to try again", error);
	ui_show_message(what, detail);
}

/* Where the credentials that are tried came from, to know what to do when Spotify rejects them */
enum credentials_source {
	CREDENTIALS_BUILD,
	CREDENTIALS_STORED,
	CREDENTIALS_HANDED_OVER,
};

/*
 * Signs in with the credentials at hand, waiting for the Spotify app to hand
 * some over when there are none. Returns with a session.
 */
static void sign_in(enum credentials_source source)
{
	while (true) {
		int ret;

		if (!zspot_credentials_available()) {
			LOG_INF("Open Spotify and select \"%s\" in the device list",
				zspot_device_name());
			ui_show_message(zspot_device_name(), "Open Spotify and pick this device");
			zspot_zeroconf_wait(-1);
			source = CREDENTIALS_HANDED_OVER;
		} else if (zspot_zeroconf_wait(0) == 0) {
			/* Handed over while an earlier attempt was waited out */
			source = CREDENTIALS_HANDED_OVER;
		}

		ui_show_message("Connecting", "Signing in to Spotify");
		ret = zspot_connect(on_event, on_pcm, NULL);
		if (ret == 0) {
			return;
		}

		LOG_ERR("zspot_connect failed (%d)", ret);
		if (ret != -EACCES) {
			k_sleep(K_SECONDS(5));
			continue;
		}

		/*
		 * Rejected. Stored credentials are of no use any more; others
		 * leave the stored ones to go back to, which are those of the
		 * account before. Without any, wait for a hand-over.
		 */
		zspot_credentials_clear();
		if (source == CREDENTIALS_STORED) {
			(void)credentials_forget();
		} else if (credentials_load() == 0) {
			LOG_INF("Going back to the stored credentials");
			source = CREDENTIALS_STORED;
		}
	}
}

int main(void)
{
	enum credentials_source source = CREDENTIALS_BUILD;
	const struct zspot_config config = {
		.device_name = CONFIG_ZSPOT_DEVICE_NAME,
		.audio_format = CONFIG_ZSPOT_AUDIO_FORMAT,
		.initial_volume = 0xFFFF, /* unity gain at the sink */
	};
	int ret;

	(void)webapi_init();
#if defined(CONFIG_ZSPOT_UI)
	if (ui_init(&ui_ops) == 0) {
		library_init();
		lyrics_init();
	}
#endif
	battery_init();
	ui_show_message("Connecting", "Waiting for the network");

	/* Without a log the screen is the only place to say what went wrong. */
	ret = network_connect();
	if (ret != 0) {
		show_failure("No network", ret);
		return 0;
	}

	pcm_tap_init();

	ret = certs_register();
	if (ret != 0) {
		show_failure("Cannot start the player", ret);
		return 0;
	}

	ret = zspot_init(&config);
	if (ret != 0) {
		LOG_ERR("zspot_init failed (%d)", ret);
		show_failure("Cannot start the player", ret);
		return 0;
	}

	ret = sink_init();
	if (ret != 0) {
		LOG_ERR("Audio sink init failed (%d)", ret);
		show_failure("No audio output", ret);
		return 0;
	}

	/* Credentials of the build are a development aid and come first. */
	if (strlen(CONFIG_ZSPOT_CREDENTIALS_JSON) > 0 &&
	    zspot_credentials_load_json(CONFIG_ZSPOT_CREDENTIALS_JSON) == 0) {
		LOG_INF("Using the credentials of the build");
	} else if (strlen(CONFIG_ZSPOT_USERNAME) > 0 &&
		   zspot_credentials_set_user_pass(CONFIG_ZSPOT_USERNAME,
						   CONFIG_ZSPOT_PASSWORD) == 0) {
		LOG_INF("Using username/password credentials");
	} else if (credentials_load() == 0) {
		LOG_INF("Using stored credentials");
		source = CREDENTIALS_STORED;
	}

	/*
	 * The Spotify app can hand credentials over at any time: the first
	 * ones, or those of another account that takes the device over.
	 */
	ret = zspot_zeroconf_start();
	if (ret != 0) {
		LOG_ERR("Zeroconf start failed (%d)", ret);
		show_failure("Cannot be found by Spotify", ret);
		return 0;
	}

	while (true) {
		sign_in(source);

		if (IS_ENABLED(CONFIG_ZSPOT_CREDENTIALS_STORED)) {
			(void)credentials_store();
		} else if (zspot_credentials_save_json(credentials_json,
						       sizeof(credentials_json)) > 0) {
			LOG_INF("Reusable credentials (store these): %s", credentials_json);
		}

		/* The last song, ready to go on with, or how to get one */
		if (!track_show(position_set)) {
			ui_show_message("Ready", "Pick this device in Spotify to start playing");
		}

		/*
		 * The protocol runs on the library threads. This one reports the
		 * end of playback and waits for another account to pick the device.
		 */
		while (zspot_zeroconf_wait(0) != 0) {
			k_sem_take(&end_sem,
				   K_MSEC(atomic_get(&end_pending) ? END_POLL_MS : IDLE_POLL_MS));
			end_poll();
		}

		LOG_INF("Another account picked the device");
		end_cancel();
		sink_flush();
		zspot_disconnect();
		source = CREDENTIALS_HANDED_OVER;
	}

	return 0;
}
```

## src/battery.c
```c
/*
 * Copyright (c) 2026 Muhammad Waleed Badar
 *
 * SPDX-License-Identifier: GPL-3.0-only
 */

#include <zephyr/device.h>
#include <zephyr/devicetree.h>
#include <zephyr/drivers/fuel_gauge.h>
#include <zephyr/kernel.h>
#include <zephyr/logging/log.h>

#include "battery.h"
#include "ui.h"

LOG_MODULE_REGISTER(battery, LOG_LEVEL_INF);

static const struct device *const gauge = DEVICE_DT_GET(DT_ALIAS(fuel_gauge0));

static void battery_poll(struct k_work *work);
static K_WORK_DELAYABLE_DEFINE(battery_work, battery_poll);

static void battery_poll(struct k_work *work)
{
	union fuel_gauge_prop_val val;
	int ret = fuel_gauge_get_prop(gauge, FUEL_GAUGE_RELATIVE_STATE_OF_CHARGE_PCT, &val);

	if (ret == 0) {
		ui_set_battery(val.relative_state_of_charge_pct);
	} else {
		/* No reading, e.g. the battery was removed: no indicator */
		LOG_DBG("Fuel gauge read failed: %d", ret);
		ui_set_battery(-1);
	}

	k_work_reschedule(&battery_work, K_SECONDS(CONFIG_ZSPOT_BATTERY_POLL_SECONDS));
}

void battery_init(void)
{
	if (!device_is_ready(gauge)) {
		LOG_WRN("Fuel gauge %s is not ready", gauge->name);
		return;
	}

	k_work_reschedule(&battery_work, K_NO_WAIT);
}
```

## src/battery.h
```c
/*
 * Copyright (c) 2026 Muhammad Waleed Badar
 *
 * SPDX-License-Identifier: GPL-3.0-only
 */

/**
 * @file
 * Battery indicator: reads the charge level from the fuel gauge behind the
 * devicetree alias fuel-gauge0 and shows it on the screen. Compiled in only
 * when the board has such a fuel gauge.
 */

#ifndef ZSPOT_SAMPLE_BATTERY_H_
#define ZSPOT_SAMPLE_BATTERY_H_

#if defined(CONFIG_ZSPOT_BATTERY)

/** Starts reading the fuel gauge periodically. Call after ui_init(). */
void battery_init(void);

#else

static inline void battery_init(void)
{
}

#endif /* CONFIG_ZSPOT_BATTERY */

#endif /* ZSPOT_SAMPLE_BATTERY_H_ */
```

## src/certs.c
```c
/*
 * Copyright (c) 2026 Muhammad Waleed Badar
 *
 * SPDX-License-Identifier: GPL-3.0-only
 */

#include "certs.h"

#include <zephyr/kernel.h>
#include <zephyr/logging/log.h>
#include <zephyr/net/tls_credentials.h>
#include <zephyr/sys/util.h>

LOG_MODULE_DECLARE(zspot_player, LOG_LEVEL_INF);

#if CONFIG_ZSPOT_TLS_SEC_TAG >= 0

static const unsigned char digicert_global_root_g2[] = {
#include "certs/digicert_global_root_g2.der.inc"
};

static const unsigned char starfield_root_g2[] = {
#include "certs/starfield_root_g2.der.inc"
};

static const unsigned char digicert_global_root_g3[] = {
#include "certs/digicert_global_root_g3.der.inc"
};

static const unsigned char globalsign_root_r3[] = {
#include "certs/globalsign_root_r3.der.inc"
};

static const unsigned char gts_root_r4[] = {
#include "certs/gts_root_r4.der.inc"
};

static const struct {
	const unsigned char *der;
	size_t len;
} roots[] = {
	{digicert_global_root_g2, sizeof(digicert_global_root_g2)},
	{starfield_root_g2, sizeof(starfield_root_g2)},
	{digicert_global_root_g3, sizeof(digicert_global_root_g3)},
	{globalsign_root_r3, sizeof(globalsign_root_r3)},
	{gts_root_r4, sizeof(gts_root_r4)},
};

/* The library offers this many tags to a connection */
BUILD_ASSERT(ARRAY_SIZE(roots) == CONFIG_ZSPOT_TLS_SEC_TAG_COUNT,
	     "CONFIG_ZSPOT_TLS_SEC_TAG_COUNT is not the number of root certificates");

int certs_register(void)
{
	for (size_t i = 0; i < ARRAY_SIZE(roots); i++) {
		int ret = tls_credential_add(CONFIG_ZSPOT_TLS_SEC_TAG + i,
					     TLS_CREDENTIAL_CA_CERTIFICATE, roots[i].der,
					     roots[i].len);

		if (ret != 0) {
			LOG_ERR("Cannot register root certificate %u (%d)", (unsigned int)i, ret);
			return ret;
		}
	}
	return 0;
}

#else

int certs_register(void)
{
	return 0;
}

#endif /* CONFIG_ZSPOT_TLS_SEC_TAG >= 0 */
```

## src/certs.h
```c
/*
 * Copyright (c) 2026 Muhammad Waleed Badar
 *
 * SPDX-License-Identifier: GPL-3.0-only
 */

/*
 * The root certificates that the servers are verified against (app/certs),
 * handed to Zephyr under the tags that the library names for its TLS
 * connections: CONFIG_ZSPOT_TLS_SEC_TAG and the CONFIG_ZSPOT_TLS_SEC_TAG_COUNT
 * that follow. With a tag of -1 nothing is verified, and nothing registered.
 */

#ifndef ZSPOT_SAMPLE_CERTS_H_
#define ZSPOT_SAMPLE_CERTS_H_

/**
 * Registers the root certificates. Call before the first connection.
 *
 * @return 0 on success or a negative errno
 */
int certs_register(void);

#endif /* ZSPOT_SAMPLE_CERTS_H_ */
```

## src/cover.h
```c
/*
 * Copyright (c) 2026 Muhammad Waleed Badar
 *
 * SPDX-License-Identifier: GPL-3.0-only
 */

#ifndef ZSPOT_SAMPLE_COVER_H_
#define ZSPOT_SAMPLE_COVER_H_

#include <lvgl.h>

/**
 * Called with the LVGL lock held once a requested cover was downloaded and
 * decoded. Ownership of @p image passes to the callee, which releases it with
 * lv_draw_buf_destroy(). @p accent is the average colour of the image.
 * @p image is NULL when the cover could not be loaded.
 */
typedef void (*cover_ready_cb_t)(lv_draw_buf_t *image, lv_color_t accent);

/**
 * Starts the cover loader thread. Call with the LVGL lock held.
 *
 * @param edge  width and height the cover is shown at: the image handed to
 *              @p ready_cb has that size, so that LVGL draws it without
 *              scaling. 0 leaves it at the size it was decoded at.
 * @return 0 on success, -ENOMEM when the LVGL pool is exhausted.
 */
int cover_init(cover_ready_cb_t ready_cb, uint32_t edge);

/**
 * Requests the JPEG behind @p url. A request that is still queued or being
 * processed is superseded: only the most recent one reaches the callback.
 * NULL or an empty URL just cancels the outstanding request.
 */
void cover_request(const char *url);

#endif /* ZSPOT_SAMPLE_COVER_H_ */
```

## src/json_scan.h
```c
/*
 * Copyright (c) 2026 Muhammad Waleed Badar
 *
 * SPDX-License-Identifier: GPL-3.0-only
 */

/*
 * Minimal read-only JSON walker for picking a few fields out of large Web API
 * responses without building a tree. The document must be NUL terminated. A
 * value is referred to by a pointer to its first character; NULL means
 * "absent" and is accepted by every function, so lookups can be chained.
 */

#ifndef ZSPOT_SAMPLE_JSON_SCAN_H_
#define ZSPOT_SAMPLE_JSON_SCAN_H_

#include <stdbool.h>
#include <stddef.h>
#include <stdint.h>

/** Value of @p key in the object @p object, or NULL. */
const char *json_member(const char *object, const char *key);

/** First element of the array @p array, or NULL when it is empty. */
const char *json_first(const char *array);

/** Element following @p element in its array, or NULL after the last one. */
const char *json_next(const char *element);

/**
 * Decodes the string @p value into @p out, truncating at a character
 * boundary. Returns false (and an empty @p out) when it is not a string.
 */
bool json_string(const char *value, char *out, size_t size);

/** Non-negative integer @p value, or @p fallback when it is not a number. */
uint32_t json_uint(const char *value, uint32_t fallback);

#endif /* ZSPOT_SAMPLE_JSON_SCAN_H_ */
```
